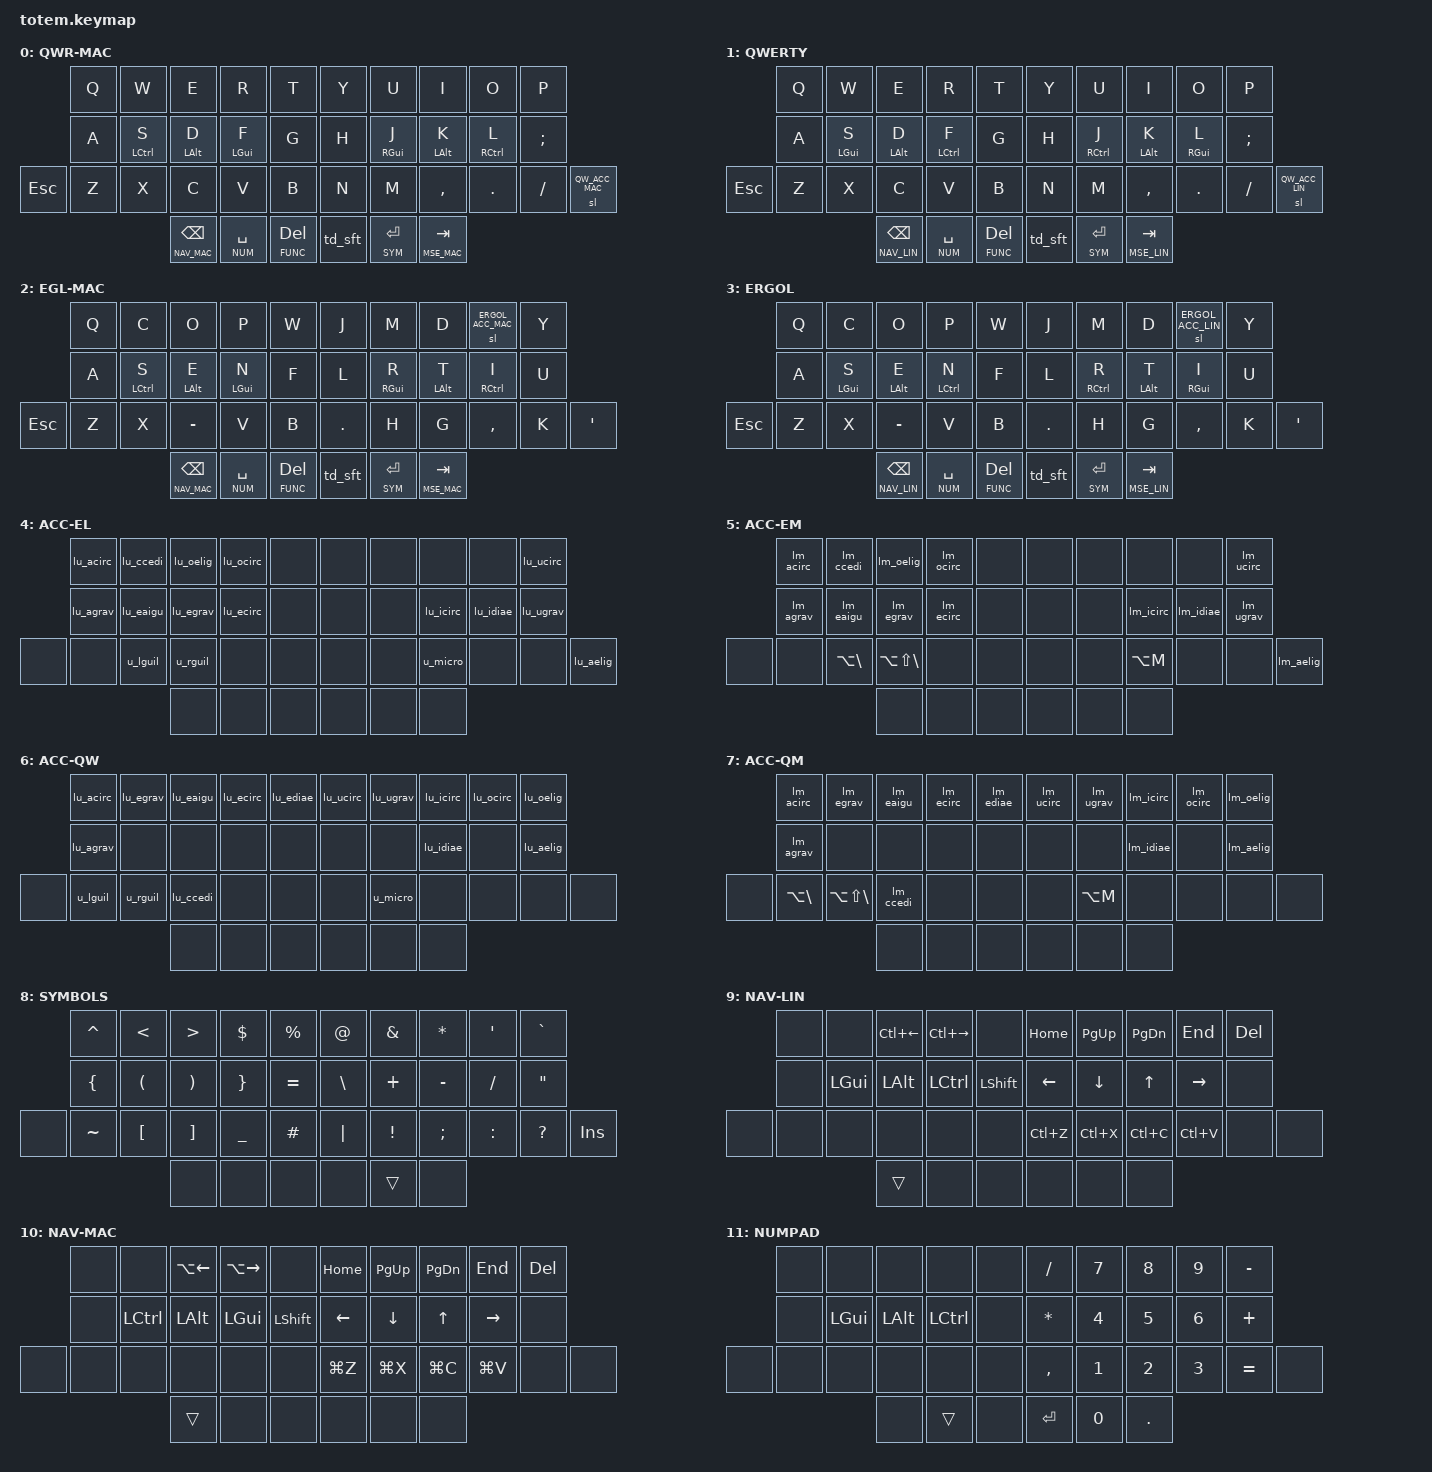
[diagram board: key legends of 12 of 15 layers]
#include <behaviors.dtsi>
#include <dt-bindings/zmk/keys.h>
#include <dt-bindings/zmk/bt.h>
#include <dt-bindings/zmk/outputs.h>
#include <dt-bindings/zmk/pointing.h>

#define QW_MAC         0
#define QWERTY         1
#define ERGOL_MAC      2
#define ERGOL          3
#define ERGOL_ACC_LIN  4
#define ERGOL_ACC_MAC  5
#define QW_ACC_LIN     6
#define QW_ACC_MAC     7
#define SYM            8
#define NAV_LIN        9
#define NAV_MAC        10
#define NUM            11
#define MSE_LIN        12
#define MSE_MAC        13
#define FUNC           14

&sl {
    release-after-ms = <1500>;
};

/ {
    behaviors {
        /* Home Row Mods */
        hrm: homerow_mods {
            compatible = "zmk,behavior-hold-tap";
            #binding-cells = <2>;
            flavor = "tap-preferred";
            tapping-term-ms = <200>;
            quick-tap-ms = <175>;
            bindings = <&kp>, <&kp>;
        };

        /* Thumb Layer-Tap (for BSPC / SPACE / DEL / RET) */
        tlt: thumb_layer_tap {
            compatible = "zmk,behavior-hold-tap";
            #binding-cells = <2>;
            flavor = "balanced";
            tapping-term-ms = <200>;
            quick-tap-ms = <175>;
            bindings = <&mo>, <&kp>;
        };

        /* Tap-Preferred Thumb Layer-Tap (instant Tab / Alt+Tab / Cmd+Tab) */
        tlt_tp: thumb_layer_tap_preferred {
            compatible = "zmk,behavior-hold-tap";
            #binding-cells = <2>;
            flavor = "tap-preferred";
            tapping-term-ms = <200>;
            quick-tap-ms = <175>;
            bindings = <&mo>, <&kp>;
        };

        /* Quick-release Sticky Shift (prevents double-capitals on fast rolls) */
        skq: sticky_key_quick_release {
            compatible = "zmk,behavior-sticky-key";
            #binding-cells = <1>;
            bindings = <&kp>;
            release-after-ms = <1000>;
            quick-release;
            ignore-modifiers;
        };

        /* Right Inner Thumb: Tap = 1-Shot Shift, Hold = Shift, Double-Tap = Caps Word */
        td_sft: tap_dance_shift_capsword {
            compatible = "zmk,behavior-tap-dance";
            #binding-cells = <0>;
            tapping-term-ms = <180>;
            bindings = <&skq LSHFT>, <&caps_word>;
        };

        /* Shift Mod-Morphs for French Accents (Linux Unicode) */
        lu_eaigu: lu_eaigu { compatible = "zmk,behavior-mod-morph"; #binding-cells = <0>; bindings = <&u_eaigu>, <&u_eaigu_cap>; mods = <(MOD_LSFT|MOD_RSFT)>; };
        lu_egrav: lu_egrav { compatible = "zmk,behavior-mod-morph"; #binding-cells = <0>; bindings = <&u_egrav>, <&u_egrav_cap>; mods = <(MOD_LSFT|MOD_RSFT)>; };
        lu_ecirc: lu_ecirc { compatible = "zmk,behavior-mod-morph"; #binding-cells = <0>; bindings = <&u_ecirc>, <&u_ecirc_cap>; mods = <(MOD_LSFT|MOD_RSFT)>; };
        lu_ediae: lu_ediae { compatible = "zmk,behavior-mod-morph"; #binding-cells = <0>; bindings = <&u_ediae>, <&u_ediae_cap>; mods = <(MOD_LSFT|MOD_RSFT)>; };
        lu_agrav: lu_agrav { compatible = "zmk,behavior-mod-morph"; #binding-cells = <0>; bindings = <&u_agrav>, <&u_agrav_cap>; mods = <(MOD_LSFT|MOD_RSFT)>; };
        lu_acirc: lu_acirc { compatible = "zmk,behavior-mod-morph"; #binding-cells = <0>; bindings = <&u_acirc>, <&u_acirc_cap>; mods = <(MOD_LSFT|MOD_RSFT)>; };
        lu_ccedi: lu_ccedi { compatible = "zmk,behavior-mod-morph"; #binding-cells = <0>; bindings = <&u_ccedi>, <&u_ccedi_cap>; mods = <(MOD_LSFT|MOD_RSFT)>; };
        lu_ocirc: lu_ocirc { compatible = "zmk,behavior-mod-morph"; #binding-cells = <0>; bindings = <&u_ocirc>, <&u_ocirc_cap>; mods = <(MOD_LSFT|MOD_RSFT)>; };
        lu_oelig: lu_oelig { compatible = "zmk,behavior-mod-morph"; #binding-cells = <0>; bindings = <&u_oelig>, <&u_oelig_cap>; mods = <(MOD_LSFT|MOD_RSFT)>; };
        lu_aelig: lu_aelig { compatible = "zmk,behavior-mod-morph"; #binding-cells = <0>; bindings = <&u_aelig>, <&u_aelig_cap>; mods = <(MOD_LSFT|MOD_RSFT)>; };
        lu_ugrav: lu_ugrav { compatible = "zmk,behavior-mod-morph"; #binding-cells = <0>; bindings = <&u_ugrav>, <&u_ugrav_cap>; mods = <(MOD_LSFT|MOD_RSFT)>; };
        lu_ucirc: lu_ucirc { compatible = "zmk,behavior-mod-morph"; #binding-cells = <0>; bindings = <&u_ucirc>, <&u_ucirc_cap>; mods = <(MOD_LSFT|MOD_RSFT)>; };
        lu_icirc: lu_icirc { compatible = "zmk,behavior-mod-morph"; #binding-cells = <0>; bindings = <&u_icirc>, <&u_icirc_cap>; mods = <(MOD_LSFT|MOD_RSFT)>; };
        lu_idiae: lu_idiae { compatible = "zmk,behavior-mod-morph"; #binding-cells = <0>; bindings = <&u_idiae>, <&u_idiae_cap>; mods = <(MOD_LSFT|MOD_RSFT)>; };

        /* Shift Mod-Morphs for French Accents (macOS Native Option Sequences) */
        lm_eaigu: lm_eaigu { compatible = "zmk,behavior-mod-morph"; #binding-cells = <0>; bindings = <&m_eaigu>, <&m_eaigu_cap>; mods = <(MOD_LSFT|MOD_RSFT)>; };
        lm_egrav: lm_egrav { compatible = "zmk,behavior-mod-morph"; #binding-cells = <0>; bindings = <&m_egrav>, <&m_egrav_cap>; mods = <(MOD_LSFT|MOD_RSFT)>; };
        lm_ecirc: lm_ecirc { compatible = "zmk,behavior-mod-morph"; #binding-cells = <0>; bindings = <&m_ecirc>, <&m_ecirc_cap>; mods = <(MOD_LSFT|MOD_RSFT)>; };
        lm_ediae: lm_ediae { compatible = "zmk,behavior-mod-morph"; #binding-cells = <0>; bindings = <&m_ediae>, <&m_ediae_cap>; mods = <(MOD_LSFT|MOD_RSFT)>; };
        lm_agrav: lm_agrav { compatible = "zmk,behavior-mod-morph"; #binding-cells = <0>; bindings = <&m_agrav>, <&m_agrav_cap>; mods = <(MOD_LSFT|MOD_RSFT)>; };
        lm_acirc: lm_acirc { compatible = "zmk,behavior-mod-morph"; #binding-cells = <0>; bindings = <&m_acirc>, <&m_acirc_cap>; mods = <(MOD_LSFT|MOD_RSFT)>; };
        lm_ccedi: lm_ccedi { compatible = "zmk,behavior-mod-morph"; #binding-cells = <0>; bindings = <&m_ccedi>, <&m_ccedi_cap>; mods = <(MOD_LSFT|MOD_RSFT)>; };
        lm_ocirc: lm_ocirc { compatible = "zmk,behavior-mod-morph"; #binding-cells = <0>; bindings = <&m_ocirc>, <&m_ocirc_cap>; mods = <(MOD_LSFT|MOD_RSFT)>; };
        lm_oelig: lm_oelig { compatible = "zmk,behavior-mod-morph"; #binding-cells = <0>; bindings = <&m_oelig>, <&m_oelig_cap>; mods = <(MOD_LSFT|MOD_RSFT)>; };
        lm_aelig: lm_aelig { compatible = "zmk,behavior-mod-morph"; #binding-cells = <0>; bindings = <&m_aelig>, <&m_aelig_cap>; mods = <(MOD_LSFT|MOD_RSFT)>; };
        lm_ugrav: lm_ugrav { compatible = "zmk,behavior-mod-morph"; #binding-cells = <0>; bindings = <&m_ugrav>, <&m_ugrav_cap>; mods = <(MOD_LSFT|MOD_RSFT)>; };
        lm_ucirc: lm_ucirc { compatible = "zmk,behavior-mod-morph"; #binding-cells = <0>; bindings = <&m_ucirc>, <&m_ucirc_cap>; mods = <(MOD_LSFT|MOD_RSFT)>; };
        lm_icirc: lm_icirc { compatible = "zmk,behavior-mod-morph"; #binding-cells = <0>; bindings = <&m_icirc>, <&m_icirc_cap>; mods = <(MOD_LSFT|MOD_RSFT)>; };
        lm_idiae: lm_idiae { compatible = "zmk,behavior-mod-morph"; #binding-cells = <0>; bindings = <&m_idiae>, <&m_idiae_cap>; mods = <(MOD_LSFT|MOD_RSFT)>; };
    };

    macros {
        /* Linux Unicode Macros (Ctrl+Shift+U + Hex + Enter) */
        u_eaigu: u_eaigu { compatible = "zmk,behavior-macro"; #binding-cells = <0>; wait-ms = <10>; tap-ms = <10>; bindings = <&kp LC(LS(U)) &kp N0 &kp N0 &kp E &kp N9 &kp RET>; };
        u_eaigu_cap: u_eaigu_cap { compatible = "zmk,behavior-macro"; #binding-cells = <0>; wait-ms = <10>; tap-ms = <10>; bindings = <&kp LC(LS(U)) &kp N0 &kp N0 &kp C &kp N9 &kp RET>; };
        u_egrav: u_egrav { compatible = "zmk,behavior-macro"; #binding-cells = <0>; wait-ms = <10>; tap-ms = <10>; bindings = <&kp LC(LS(U)) &kp N0 &kp N0 &kp E &kp N8 &kp RET>; };
        u_egrav_cap: u_egrav_cap { compatible = "zmk,behavior-macro"; #binding-cells = <0>; wait-ms = <10>; tap-ms = <10>; bindings = <&kp LC(LS(U)) &kp N0 &kp N0 &kp C &kp N8 &kp RET>; };
        u_ecirc: u_ecirc { compatible = "zmk,behavior-macro"; #binding-cells = <0>; wait-ms = <10>; tap-ms = <10>; bindings = <&kp LC(LS(U)) &kp N0 &kp N0 &kp E &kp A &kp RET>; };
        u_ecirc_cap: u_ecirc_cap { compatible = "zmk,behavior-macro"; #binding-cells = <0>; wait-ms = <10>; tap-ms = <10>; bindings = <&kp LC(LS(U)) &kp N0 &kp N0 &kp C &kp A &kp RET>; };
        u_ediae: u_ediae { compatible = "zmk,behavior-macro"; #binding-cells = <0>; wait-ms = <10>; tap-ms = <10>; bindings = <&kp LC(LS(U)) &kp N0 &kp N0 &kp E &kp B &kp RET>; };
        u_ediae_cap: u_ediae_cap { compatible = "zmk,behavior-macro"; #binding-cells = <0>; wait-ms = <10>; tap-ms = <10>; bindings = <&kp LC(LS(U)) &kp N0 &kp N0 &kp C &kp B &kp RET>; };
        u_agrav: u_agrav { compatible = "zmk,behavior-macro"; #binding-cells = <0>; wait-ms = <10>; tap-ms = <10>; bindings = <&kp LC(LS(U)) &kp N0 &kp N0 &kp E &kp N0 &kp RET>; };
        u_agrav_cap: u_agrav_cap { compatible = "zmk,behavior-macro"; #binding-cells = <0>; wait-ms = <10>; tap-ms = <10>; bindings = <&kp LC(LS(U)) &kp N0 &kp N0 &kp C &kp N0 &kp RET>; };
        u_acirc: u_acirc { compatible = "zmk,behavior-macro"; #binding-cells = <0>; wait-ms = <10>; tap-ms = <10>; bindings = <&kp LC(LS(U)) &kp N0 &kp N0 &kp E &kp N2 &kp RET>; };
        u_acirc_cap: u_acirc_cap { compatible = "zmk,behavior-macro"; #binding-cells = <0>; wait-ms = <10>; tap-ms = <10>; bindings = <&kp LC(LS(U)) &kp N0 &kp N0 &kp C &kp N2 &kp RET>; };
        u_ccedi: u_ccedi { compatible = "zmk,behavior-macro"; #binding-cells = <0>; wait-ms = <10>; tap-ms = <10>; bindings = <&kp LC(LS(U)) &kp N0 &kp N0 &kp E &kp N7 &kp RET>; };
        u_ccedi_cap: u_ccedi_cap { compatible = "zmk,behavior-macro"; #binding-cells = <0>; wait-ms = <10>; tap-ms = <10>; bindings = <&kp LC(LS(U)) &kp N0 &kp N0 &kp C &kp N7 &kp RET>; };
        u_ocirc: u_ocirc { compatible = "zmk,behavior-macro"; #binding-cells = <0>; wait-ms = <10>; tap-ms = <10>; bindings = <&kp LC(LS(U)) &kp N0 &kp N0 &kp F &kp N4 &kp RET>; };
        u_ocirc_cap: u_ocirc_cap { compatible = "zmk,behavior-macro"; #binding-cells = <0>; wait-ms = <10>; tap-ms = <10>; bindings = <&kp LC(LS(U)) &kp N0 &kp N0 &kp D &kp N4 &kp RET>; };
        u_oelig: u_oelig { compatible = "zmk,behavior-macro"; #binding-cells = <0>; wait-ms = <10>; tap-ms = <10>; bindings = <&kp LC(LS(U)) &kp N0 &kp N1 &kp N5 &kp N3 &kp RET>; };
        u_oelig_cap: u_oelig_cap { compatible = "zmk,behavior-macro"; #binding-cells = <0>; wait-ms = <10>; tap-ms = <10>; bindings = <&kp LC(LS(U)) &kp N0 &kp N1 &kp N5 &kp N2 &kp RET>; };
        u_aelig: u_aelig { compatible = "zmk,behavior-macro"; #binding-cells = <0>; wait-ms = <10>; tap-ms = <10>; bindings = <&kp LC(LS(U)) &kp N0 &kp N0 &kp E &kp N6 &kp RET>; };
        u_aelig_cap: u_aelig_cap { compatible = "zmk,behavior-macro"; #binding-cells = <0>; wait-ms = <10>; tap-ms = <10>; bindings = <&kp LC(LS(U)) &kp N0 &kp N0 &kp C &kp N6 &kp RET>; };
        u_ugrav: u_ugrav { compatible = "zmk,behavior-macro"; #binding-cells = <0>; wait-ms = <10>; tap-ms = <10>; bindings = <&kp LC(LS(U)) &kp N0 &kp N0 &kp F &kp N9 &kp RET>; };
        u_ugrav_cap: u_ugrav_cap { compatible = "zmk,behavior-macro"; #binding-cells = <0>; wait-ms = <10>; tap-ms = <10>; bindings = <&kp LC(LS(U)) &kp N0 &kp N0 &kp D &kp N9 &kp RET>; };
        u_ucirc: u_ucirc { compatible = "zmk,behavior-macro"; #binding-cells = <0>; wait-ms = <10>; tap-ms = <10>; bindings = <&kp LC(LS(U)) &kp N0 &kp N0 &kp F &kp B &kp RET>; };
        u_ucirc_cap: u_ucirc_cap { compatible = "zmk,behavior-macro"; #binding-cells = <0>; wait-ms = <10>; tap-ms = <10>; bindings = <&kp LC(LS(U)) &kp N0 &kp N0 &kp D &kp B &kp RET>; };
        u_icirc: u_icirc { compatible = "zmk,behavior-macro"; #binding-cells = <0>; wait-ms = <10>; tap-ms = <10>; bindings = <&kp LC(LS(U)) &kp N0 &kp N0 &kp E &kp E &kp RET>; };
        u_icirc_cap: u_icirc_cap { compatible = "zmk,behavior-macro"; #binding-cells = <0>; wait-ms = <10>; tap-ms = <10>; bindings = <&kp LC(LS(U)) &kp N0 &kp N0 &kp C &kp E &kp RET>; };
        u_idiae: u_idiae { compatible = "zmk,behavior-macro"; #binding-cells = <0>; wait-ms = <10>; tap-ms = <10>; bindings = <&kp LC(LS(U)) &kp N0 &kp N0 &kp E &kp F &kp RET>; };
        u_idiae_cap: u_idiae_cap { compatible = "zmk,behavior-macro"; #binding-cells = <0>; wait-ms = <10>; tap-ms = <10>; bindings = <&kp LC(LS(U)) &kp N0 &kp N0 &kp C &kp F &kp RET>; };
        u_lguil: u_lguil { compatible = "zmk,behavior-macro"; #binding-cells = <0>; wait-ms = <10>; tap-ms = <10>; bindings = <&kp LC(LS(U)) &kp N0 &kp N0 &kp A &kp B &kp RET>; };
        u_rguil: u_rguil { compatible = "zmk,behavior-macro"; #binding-cells = <0>; wait-ms = <10>; tap-ms = <10>; bindings = <&kp LC(LS(U)) &kp N0 &kp N0 &kp B &kp B &kp RET>; };
        u_micro: u_micro { compatible = "zmk,behavior-macro"; #binding-cells = <0>; wait-ms = <10>; tap-ms = <10>; bindings = <&kp LC(LS(U)) &kp N0 &kp N0 &kp B &kp N5 &kp RET>; };

        /* macOS Option Macros (Standard US Layout) */
        m_eaigu: m_eaigu { compatible = "zmk,behavior-macro"; #binding-cells = <0>; wait-ms = <10>; tap-ms = <10>; bindings = <&kp LA(E) &kp E>; };
        m_eaigu_cap: m_eaigu_cap { compatible = "zmk,behavior-macro"; #binding-cells = <0>; wait-ms = <10>; tap-ms = <10>; bindings = <&kp LA(E) &kp LS(E)>; };
        m_egrav: m_egrav { compatible = "zmk,behavior-macro"; #binding-cells = <0>; wait-ms = <10>; tap-ms = <10>; bindings = <&kp LA(GRAVE) &kp E>; };
        m_egrav_cap: m_egrav_cap { compatible = "zmk,behavior-macro"; #binding-cells = <0>; wait-ms = <10>; tap-ms = <10>; bindings = <&kp LA(GRAVE) &kp LS(E)>; };
        m_ecirc: m_ecirc { compatible = "zmk,behavior-macro"; #binding-cells = <0>; wait-ms = <10>; tap-ms = <10>; bindings = <&kp LA(I) &kp E>; };
        m_ecirc_cap: m_ecirc_cap { compatible = "zmk,behavior-macro"; #binding-cells = <0>; wait-ms = <10>; tap-ms = <10>; bindings = <&kp LA(I) &kp LS(E)>; };
        m_ediae: m_ediae { compatible = "zmk,behavior-macro"; #binding-cells = <0>; wait-ms = <10>; tap-ms = <10>; bindings = <&kp LA(U) &kp E>; };
        m_ediae_cap: m_ediae_cap { compatible = "zmk,behavior-macro"; #binding-cells = <0>; wait-ms = <10>; tap-ms = <10>; bindings = <&kp LA(U) &kp LS(E)>; };
        m_agrav: m_agrav { compatible = "zmk,behavior-macro"; #binding-cells = <0>; wait-ms = <10>; tap-ms = <10>; bindings = <&kp LA(GRAVE) &kp A>; };
        m_agrav_cap: m_agrav_cap { compatible = "zmk,behavior-macro"; #binding-cells = <0>; wait-ms = <10>; tap-ms = <10>; bindings = <&kp LA(GRAVE) &kp LS(A)>; };
        m_acirc: m_acirc { compatible = "zmk,behavior-macro"; #binding-cells = <0>; wait-ms = <10>; tap-ms = <10>; bindings = <&kp LA(I) &kp A>; };
        m_acirc_cap: m_acirc_cap { compatible = "zmk,behavior-macro"; #binding-cells = <0>; wait-ms = <10>; tap-ms = <10>; bindings = <&kp LA(I) &kp LS(A)>; };
        m_ccedi: m_ccedi { compatible = "zmk,behavior-macro"; #binding-cells = <0>; wait-ms = <10>; tap-ms = <10>; bindings = <&kp LA(C)>; };
        m_ccedi_cap: m_ccedi_cap { compatible = "zmk,behavior-macro"; #binding-cells = <0>; wait-ms = <10>; tap-ms = <10>; bindings = <&kp LA(LS(C))>; };
        m_ocirc: m_ocirc { compatible = "zmk,behavior-macro"; #binding-cells = <0>; wait-ms = <10>; tap-ms = <10>; bindings = <&kp LA(I) &kp O>; };
        m_ocirc_cap: m_ocirc_cap { compatible = "zmk,behavior-macro"; #binding-cells = <0>; wait-ms = <10>; tap-ms = <10>; bindings = <&kp LA(I) &kp LS(O)>; };
        m_oelig: m_oelig { compatible = "zmk,behavior-macro"; #binding-cells = <0>; wait-ms = <10>; tap-ms = <10>; bindings = <&kp LA(Q)>; };
        m_oelig_cap: m_oelig_cap { compatible = "zmk,behavior-macro"; #binding-cells = <0>; wait-ms = <10>; tap-ms = <10>; bindings = <&kp LA(LS(Q))>; };
        m_aelig: m_aelig { compatible = "zmk,behavior-macro"; #binding-cells = <0>; wait-ms = <10>; tap-ms = <10>; bindings = <&kp LA(SQT)>; };
        m_aelig_cap: m_aelig_cap { compatible = "zmk,behavior-macro"; #binding-cells = <0>; wait-ms = <10>; tap-ms = <10>; bindings = <&kp LA(LS(SQT))>; };
        m_ugrav: m_ugrav { compatible = "zmk,behavior-macro"; #binding-cells = <0>; wait-ms = <10>; tap-ms = <10>; bindings = <&kp LA(GRAVE) &kp U>; };
        m_ugrav_cap: m_ugrav_cap { compatible = "zmk,behavior-macro"; #binding-cells = <0>; wait-ms = <10>; tap-ms = <10>; bindings = <&kp LA(GRAVE) &kp LS(U)>; };
        m_ucirc: m_ucirc { compatible = "zmk,behavior-macro"; #binding-cells = <0>; wait-ms = <10>; tap-ms = <10>; bindings = <&kp LA(I) &kp U>; };
        m_ucirc_cap: m_ucirc_cap { compatible = "zmk,behavior-macro"; #binding-cells = <0>; wait-ms = <10>; tap-ms = <10>; bindings = <&kp LA(I) &kp LS(U)>; };
        m_icirc: m_icirc { compatible = "zmk,behavior-macro"; #binding-cells = <0>; wait-ms = <10>; tap-ms = <10>; bindings = <&kp LA(I) &kp I>; };
        m_icirc_cap: m_icirc_cap { compatible = "zmk,behavior-macro"; #binding-cells = <0>; wait-ms = <10>; tap-ms = <10>; bindings = <&kp LA(I) &kp LS(I)>; };
        m_idiae: m_idiae { compatible = "zmk,behavior-macro"; #binding-cells = <0>; wait-ms = <10>; tap-ms = <10>; bindings = <&kp LA(U) &kp I>; };
        m_idiae_cap: m_idiae_cap { compatible = "zmk,behavior-macro"; #binding-cells = <0>; wait-ms = <10>; tap-ms = <10>; bindings = <&kp LA(U) &kp LS(I)>; };
    };

    keymap {
        compatible = "zmk,keymap";

        /* Layer 0: QWERTY (macOS Mode - Default on Boot) */
        qwerty_mac_layer {
            display-name = "QWR-MAC";
            bindings = <
                &kp Q          &kp W          &kp E          &kp R          &kp T               &kp Y          &kp U          &kp I          &kp O          &kp P
                &kp A          &hrm LCTRL S   &hrm LALT D    &hrm LGUI F    &kp G               &kp H          &hrm RGUI J    &hrm LALT K    &hrm RCTRL L   &kp SEMI
    &kp ESC     &kp Z          &kp X          &kp C          &kp V          &kp B               &kp N          &kp M          &kp COMMA      &kp DOT        &kp FSLH       &sl QW_ACC_MAC
                                              &tlt NAV_MAC BSPC &tlt NUM SPACE &tlt FUNC DEL    &td_sft        &tlt SYM RET   &tlt_tp MSE_MAC TAB
            >;
        };

        /* Layer 1: QWERTY (Linux Mode) */
        qwerty_layer {
            display-name = "QWERTY";
            bindings = <
                &kp Q          &kp W          &kp E          &kp R          &kp T               &kp Y          &kp U          &kp I          &kp O          &kp P
                &kp A          &hrm LGUI S    &hrm LALT D    &hrm LCTRL F   &kp G               &kp H          &hrm RCTRL J   &hrm LALT K    &hrm RGUI L    &kp SEMI
    &kp ESC     &kp Z          &kp X          &kp C          &kp V          &kp B               &kp N          &kp M          &kp COMMA      &kp DOT        &kp FSLH       &sl QW_ACC_LIN
                                              &tlt NAV_LIN BSPC &tlt NUM SPACE &tlt FUNC DEL    &td_sft        &tlt SYM RET   &tlt_tp MSE_LIN TAB
            >;
        };

        /* Layer 2: Ergo-L (macOS Mode) */
        ergol_mac_layer {
            display-name = "EGL-MAC";
            bindings = <
                &kp Q          &kp C          &kp O          &kp P          &kp W               &kp J          &kp M          &kp D          &sl ERGOL_ACC_MAC &kp Y
                &kp A          &hrm LCTRL S   &hrm LALT E    &hrm LGUI N    &kp F               &kp L          &hrm RGUI R    &hrm LALT T    &hrm RCTRL I   &kp U
    &kp ESC     &kp Z          &kp X          &kp MINUS      &kp V          &kp B               &kp DOT        &kp H          &kp G          &kp COMMA      &kp K          &kp SQT
                                              &tlt NAV_MAC BSPC &tlt NUM SPACE &tlt FUNC DEL    &td_sft        &tlt SYM RET   &tlt_tp MSE_MAC TAB
            >;
        };

        /* Layer 3: Ergo-L (Linux Mode) */
        ergol_layer {
            display-name = "ERGOL";
            bindings = <
                &kp Q          &kp C          &kp O          &kp P          &kp W               &kp J          &kp M          &kp D          &sl ERGOL_ACC_LIN &kp Y
                &kp A          &hrm LGUI S    &hrm LALT E    &hrm LCTRL N   &kp F               &kp L          &hrm RCTRL R   &hrm LALT T    &hrm RGUI I    &kp U
    &kp ESC     &kp Z          &kp X          &kp MINUS      &kp V          &kp B               &kp DOT        &kp H          &kp G          &kp COMMA      &kp K          &kp SQT
                                              &tlt NAV_LIN BSPC &tlt NUM SPACE &tlt FUNC DEL    &td_sft        &tlt SYM RET   &tlt_tp MSE_LIN TAB
            >;
        };

        /* Layer 4: Ergo-L French Accents (Linux) */
        ergol_acc_lin_layer {
            display-name = "ACC-EL";
            bindings = <
                &lu_acirc      &lu_ccedi      &lu_oelig      &lu_ocirc      &none               &none          &none          &none          &none          &lu_ucirc
                &lu_agrav      &lu_eaigu      &lu_egrav      &lu_ecirc      &none               &none          &none          &lu_icirc      &lu_idiae      &lu_ugrav
    &none       &none          &u_lguil       &u_rguil       &none          &none               &none          &none          &u_micro       &none          &none          &lu_aelig
                                              &none          &none          &none               &none          &none          &none
            >;
        };

        /* Layer 5: Ergo-L French Accents (macOS) */
        ergol_acc_mac_layer {
            display-name = "ACC-EM";
            bindings = <
                &lm_acirc      &lm_ccedi      &lm_oelig      &lm_ocirc      &none               &none          &none          &none          &none          &lm_ucirc
                &lm_agrav      &lm_eaigu      &lm_egrav      &lm_ecirc      &none               &none          &none          &lm_icirc      &lm_idiae      &lm_ugrav
    &none       &none          &kp LA(BSLH)   &kp LA(LS(BSLH)) &none        &none               &none          &none          &kp LA(M)      &none          &none          &lm_aelig
                                              &none          &none          &none               &none          &none          &none
            >;
        };

        /* Layer 6: QWERTY French Accents (Linux) */
        qwerty_acc_lin_layer {
            display-name = "ACC-QW";
            bindings = <
                &lu_acirc      &lu_egrav      &lu_eaigu      &lu_ecirc      &lu_ediae           &lu_ucirc      &lu_ugrav      &lu_icirc      &lu_ocirc      &lu_oelig
                &lu_agrav      &none          &none          &none          &none               &none          &none          &lu_idiae      &none          &lu_aelig
    &none       &u_lguil       &u_rguil       &lu_ccedi      &none          &none               &none          &u_micro       &none          &none          &none          &none
                                              &none          &none          &none               &none          &none          &none
            >;
        };

        /* Layer 7: QWERTY French Accents (macOS) */
        qwerty_acc_mac_layer {
            display-name = "ACC-QM";
            bindings = <
                &lm_acirc      &lm_egrav      &lm_eaigu      &lm_ecirc      &lm_ediae           &lm_ucirc      &lm_ugrav      &lm_icirc      &lm_ocirc      &lm_oelig
                &lm_agrav      &none          &none          &none          &none               &none          &none          &lm_idiae      &none          &lm_aelig
    &none       &kp LA(BSLH)   &kp LA(LS(BSLH)) &lm_ccedi    &none          &none               &none          &kp LA(M)      &none          &none          &none          &none
                                              &none          &none          &none               &none          &none          &none
            >;
        };

        /* Layer 8: Programming Symbols (Unshifted Inward Rolls) */
        sym_layer {
            display-name = "SYMBOLS";
            bindings = <
                &kp CARET      &kp LT         &kp GT         &kp DLLR       &kp PRCNT           &kp AT         &kp AMPS       &kp ASTRK      &kp SQT        &kp GRAVE
                &kp LBRC       &kp LPAR       &kp RPAR       &kp RBRC       &kp EQUAL           &kp BSLH       &kp PLUS       &kp MINUS      &kp FSLH       &kp DQT
    &none       &kp TILDE      &kp LBKT       &kp RBKT       &kp UNDER      &kp HASH       &kp PIPE       &kp EXCL       &kp SEMI       &kp COLON      &kp QMARK      &kp INS
                                              &none          &none          &none               &none          &trans         &none
            >;
        };

        /* Layer 9: Navigation & Clipboard (Linux Shortcuts - Hold Left Outer Thumb) */
        nav_lin_layer {
            display-name = "NAV-LIN";
            bindings = <
                &none          &none          &kp LC(LEFT)   &kp LC(RIGHT)  &none               &kp HOME       &kp PG_UP      &kp PG_DN      &kp END        &kp DEL
                &none          &kp LGUI       &kp LALT       &kp LCTRL      &kp LSHFT           &kp LEFT       &kp DOWN       &kp UP         &kp RIGHT      &none
    &none       &none          &none          &none          &none          &none               &kp LC(Z)      &kp LC(X)      &kp LC(C)      &kp LC(V)      &none          &none
                                              &trans         &none          &none              &none          &none          &none 
            >;
        };

        /* Layer 10: Navigation & Clipboard (macOS Shortcuts - Hold Left Outer Thumb) */
        nav_mac_layer {
            display-name = "NAV-MAC";
            bindings = <
                &none          &none          &kp LA(LEFT)   &kp LA(RIGHT)  &none               &kp HOME       &kp PG_UP      &kp PG_DN      &kp END        &kp DEL
                &none          &kp LCTRL      &kp LALT       &kp LGUI       &kp LSHFT           &kp LEFT       &kp DOWN       &kp UP         &kp RIGHT      &none
    &none       &none          &none          &none          &none          &none               &kp LG(Z)      &kp LG(X)      &kp LG(C)      &kp LG(V)      &none          &none
                                              &trans         &none          &none               &none          &none          &none
            >;
        };

        /* Layer 11: Numpad (Hold Left Middle Thumb) */
        num_layer {
            display-name = "NUMPAD";
            bindings = <
                &none          &none          &none          &none          &none               &kp FSLH       &kp N7         &kp N8         &kp N9         &kp MINUS
                &none          &kp LGUI       &kp LALT       &kp LCTRL      &none               &kp ASTRK      &kp N4         &kp N5         &kp N6         &kp PLUS
    &none       &none          &none          &none          &none          &none               &kp COMMA      &kp N1         &kp N2         &kp N3         &kp EQUAL      &none
                                              &none          &trans         &none               &kp RET        &kp N0         &kp DOT
            >;
        };

        /* Layer 12: Mouse, Media & Brightness (Linux - Hold Right Outer Thumb) */
        mouse_lin_layer {
            display-name = "MSE-LIN";
            bindings = <
                &none          &msc SCRL_UP   &mmv MOVE_UP   &msc SCRL_DOWN &none               &none          &kp C_BRI_DN   &kp C_BRI_UP   &none          &none
                &none          &mmv MOVE_LEFT &mmv MOVE_DOWN &mmv MOVE_RIGHT &none              &kp LSHFT      &kp RCTRL      &kp LALT       &kp RGUI       &none
    &none       &none          &none          &kp LA(LEFT)   &kp LA(RIGHT)  &none               &kp C_VOL_DN   &kp C_MUTE     &kp C_PP       &kp C_VOL_UP   &none          &none
                                              &mkp LCLK      &mkp RCLK      &mkp MCLK           &none          &none          &trans
            >;
        };

        /* Layer 13: Mouse, Media & Brightness (macOS - Hold Right Outer Thumb) */
        mouse_mac_layer {
            display-name = "MSE-MAC";
            bindings = <
                &none          &msc SCRL_UP   &mmv MOVE_UP   &msc SCRL_DOWN &none               &none          &kp C_BRI_DN   &kp C_BRI_UP   &none          &none
                &none          &mmv MOVE_LEFT &mmv MOVE_DOWN &mmv MOVE_RIGHT &none              &kp LSHFT      &kp RGUI       &kp LALT       &kp RCTRL      &none
    &none       &none          &none          &kp LG(LBKT)   &kp LG(RBKT)   &none               &kp C_VOL_DN   &kp C_MUTE     &kp C_PP       &kp C_VOL_UP   &none          &none
                                              &mkp LCLK      &mkp RCLK      &mkp MCLK           &none          &none          &trans
            >;
        };

        /* Layer 14: Function & System (Hold Left Inner Thumb) */
        func_layer {
            display-name = "FN-SYS";
            bindings = <
                &bt BT_SEL 0   &bt BT_SEL 1   &bt BT_SEL 2   &to ERGOL      &to ERGOL_MAC       &none          &kp F7         &kp F8         &kp F9         &none
                &none          &kp LCTRL      &kp LALT       &kp LGUI       &none               &none          &kp F4         &kp F5         &kp F6         &none
    &kp CAPS    &bt BT_CLR     &out OUT_TOG   &none          &to QWERTY     &to QW_MAC      &none          &kp F1         &kp F2         &kp F3         &none          &bootloader
                                              &none          &none          &trans              &kp F10        &kp F11        &kp F12
            >;
        };
    };
};
